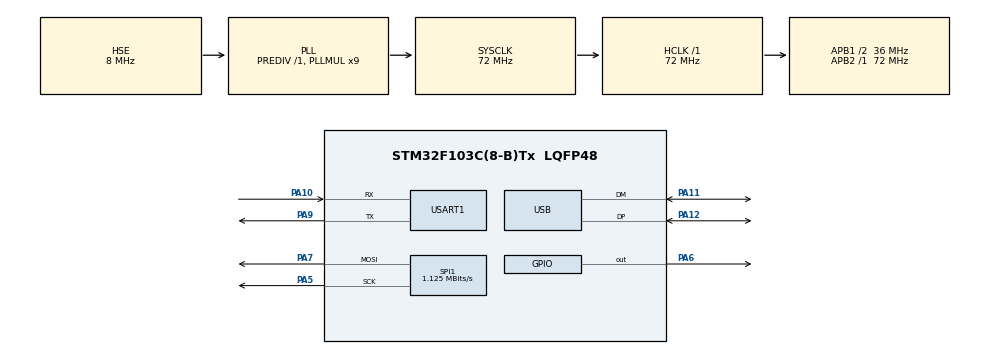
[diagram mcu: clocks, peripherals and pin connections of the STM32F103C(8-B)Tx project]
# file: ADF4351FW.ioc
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Dma.Request0=USART1_RX
Dma.Request1=USART1_TX
Dma.Request2=SPI1_TX
Dma.SPI1_TX.2.Direction=DMA_MEMORY_TO_PERIPH
Dma.SPI1_TX.2.Instance=DMA1_Channel3
Dma.SPI1_TX.2.MemDataAlignment=DMA_MDATAALIGN_BYTE
Dma.SPI1_TX.2.MemInc=DMA_MINC_ENABLE
Dma.SPI1_TX.2.Mode=DMA_NORMAL
Dma.SPI1_TX.2.PeriphDataAlignment=DMA_PDATAALIGN_BYTE
Dma.SPI1_TX.2.PeriphInc=DMA_PINC_DISABLE
Dma.SPI1_TX.2.Priority=DMA_PRIORITY_LOW
Dma.USART1_RX.0.Direction=DMA_PERIPH_TO_MEMORY
Dma.USART1_RX.0.Instance=DMA1_Channel5
Dma.USART1_RX.0.MemDataAlignment=DMA_MDATAALIGN_BYTE
Dma.USART1_RX.0.MemInc=DMA_MINC_ENABLE
Dma.USART1_RX.0.Mode=DMA_NORMAL
Dma.USART1_RX.0.PeriphDataAlignment=DMA_PDATAALIGN_BYTE
Dma.USART1_RX.0.PeriphInc=DMA_PINC_DISABLE
Dma.USART1_RX.0.Priority=DMA_PRIORITY_LOW
Dma.USART1_TX.1.Direction=DMA_MEMORY_TO_PERIPH
Dma.USART1_TX.1.Instance=DMA1_Channel4
Dma.USART1_TX.1.MemDataAlignment=DMA_MDATAALIGN_BYTE
Dma.USART1_TX.1.MemInc=DMA_MINC_ENABLE
Dma.USART1_TX.1.Mode=DMA_NORMAL
Dma.USART1_TX.1.PeriphDataAlignment=DMA_PDATAALIGN_BYTE
Dma.USART1_TX.1.PeriphInc=DMA_PINC_DISABLE
Dma.USART1_TX.1.Priority=DMA_PRIORITY_LOW
Mcu.Family=STM32F1
Mcu.Name=STM32F103C(8-B)Tx
Mcu.Package=LQFP48
NVIC.DMA1_Channel3_IRQn=true\:0\:0\:false\:false\:true\:false
NVIC.DMA1_Channel4_IRQn=true\:0\:0\:false\:false\:true\:false
NVIC.DMA1_Channel5_IRQn=true\:0\:0\:false\:false\:true\:false
NVIC.PriorityGroup=NVIC_PRIORITYGROUP_4
NVIC.USB_LP_CAN1_RX0_IRQn=true\:0\:0\:false\:false\:true\:false
PA10.Mode=Asynchronous
PA10.Signal=USART1_RX
PA11.Mode=Device
PA11.Signal=USB_DM
PA12.Mode=Device
PA12.Signal=USB_DP
PA13.Mode=Serial_Wire
PA13.Signal=SYS_JTMS-SWDIO
PA14.Mode=Serial_Wire
PA14.Signal=SYS_JTCK-SWCLK
PA5.Mode=TX_Only_Simplex_Unidirect_Master
PA5.Signal=SPI1_SCK
PA6.GPIO_Speed=GPIO_SPEED_FREQ_HIGH
PA6.PinState=GPIO_PIN_SET
PA6.Signal=GPIO_Output
PA7.Mode=TX_Only_Simplex_Unidirect_Master
PA7.Signal=SPI1_MOSI
PA9.Mode=Asynchronous
PA9.Signal=USART1_TX
PC14-OSC32_IN.Mode=LSE-External-Oscillator
PC14-OSC32_IN.Signal=RCC_OSC32_IN
PC15-OSC32_OUT.Mode=LSE-External-Oscillator
PC15-OSC32_OUT.Signal=RCC_OSC32_OUT
PD0-OSC_IN.Mode=HSE-External-Oscillator
PD0-OSC_IN.Signal=RCC_OSC_IN
PD1-OSC_OUT.Mode=HSE-External-Oscillator
PD1-OSC_OUT.Signal=RCC_OSC_OUT
ProjectManager.HeapSize=0x200
ProjectManager.StackSize=0x400
ProjectManager.TargetToolchain=SW4STM32
RCC.AHBFreq_Value=72000000
RCC.APB1CLKDivider=RCC_HCLK_DIV2
RCC.APB1Freq_Value=36000000
RCC.APB1TimFreq_Value=72000000
RCC.APB2Freq_Value=72000000
RCC.APB2TimFreq_Value=72000000
RCC.HCLKFreq_Value=72000000
RCC.PLLMUL=RCC_PLL_MUL9
RCC.SYSCLKFreq_VALUE=72000000
RCC.SYSCLKSource=RCC_SYSCLKSOURCE_PLLCLK
RCC.USBFreq_Value=48000000
RCC.USBPrescaler=RCC_USBCLKSOURCE_PLL_DIV1_5
SPI1.BaudRatePrescaler=SPI_BAUDRATEPRESCALER_64
SPI1.CalculateBaudRate=1.125 MBits/s
SPI1.DataSize=SPI_DATASIZE_8BIT
SPI1.Direction=SPI_DIRECTION_2LINES
SPI1.Mode=SPI_MODE_MASTER
SPI1.VirtualType=VM_MASTER
USART1.VirtualMode=VM_ASYNC
USB_DEVICE.CLASS_NAME_FS=CUSTOMHID
USB_DEVICE.USBD_CUSTOMHID_OUTREPORT_BUF_SIZE=64
USB_DEVICE.USBD_SELF_POWERED=0
USB_DEVICE.VirtualMode=CustomHid
USB_DEVICE.VirtualModeFS=Custom_Hid_FS
VP_USB_DEVICE_VS_USB_DEVICE_CUSTOM_HID_FS.Mode=CUSTOM_HID_FS
board=ADF4351FW

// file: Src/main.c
/**
  ******************************************************************************
  * @file           : main.c
  * @brief          : Main program body
  ******************************************************************************
  * This notice applies to any and all portions of this file
  * that are not between comment pairs USER CODE BEGIN and
  * USER CODE END. Other portions of this file, whether
  * inserted by the user or by software development tools
  * are owned by their respective copyright owners.
  *
  * Copyright (c) 2018 STMicroelectronics International N.V.
  * All rights reserved.
  *
  * Redistribution and use in source and binary forms, with or without
  * modification, are permitted, provided that the following conditions are met:
  *
  * 1. Redistribution of source code must retain the above copyright notice,
  *    this list of conditions and the following disclaimer.
  * 2. Redistributions in binary form must reproduce the above copyright notice,
  *    this list of conditions and the following disclaimer in the documentation
  *    and/or other materials provided with the distribution.
  * 3. Neither the name of STMicroelectronics nor the names of other
  *    contributors to this software may be used to endorse or promote products
  *    derived from this software without specific written permission.
  * 4. This software, including modifications and/or derivative works of this
  *    software, must execute solely and exclusively on microcontroller or
  *    microprocessor devices manufactured by or for STMicroelectronics.
  * 5. Redistribution and use of this software other than as permitted under
  *    this license is void and will automatically terminate your rights under
  *    this license.
  *
  * THIS SOFTWARE IS PROVIDED BY STMICROELECTRONICS AND CONTRIBUTORS "AS IS"
  * AND ANY EXPRESS, IMPLIED OR STATUTORY WARRANTIES, INCLUDING, BUT NOT
  * LIMITED TO, THE IMPLIED WARRANTIES OF MERCHANTABILITY, FITNESS FOR A
  * PARTICULAR PURPOSE AND NON-INFRINGEMENT OF THIRD PARTY INTELLECTUAL PROPERTY
  * RIGHTS ARE DISCLAIMED TO THE FULLEST EXTENT PERMITTED BY LAW. IN NO EVENT
  * SHALL STMICROELECTRONICS OR CONTRIBUTORS BE LIABLE FOR ANY DIRECT, INDIRECT,
  * INCIDENTAL, SPECIAL, EXEMPLARY, OR CONSEQUENTIAL DAMAGES (INCLUDING, BUT NOT
  * LIMITED TO, PROCUREMENT OF SUBSTITUTE GOODS OR SERVICES; LOSS OF USE, DATA,
  * OR PROFITS; OR BUSINESS INTERRUPTION) HOWEVER CAUSED AND ON ANY THEORY OF
  * LIABILITY, WHETHER IN CONTRACT, STRICT LIABILITY, OR TORT (INCLUDING
  * NEGLIGENCE OR OTHERWISE) ARISING IN ANY WAY OUT OF THE USE OF THIS SOFTWARE,
  * EVEN IF ADVISED OF THE POSSIBILITY OF SUCH DAMAGE.
  *
  ******************************************************************************
  */
#include "main.h"
#include "stm32f1xx_hal.h"
#include "usb_device.h"
#include "data_sender.h"

SPI_HandleTypeDef hspi1;
DMA_HandleTypeDef hdma_spi1_tx;

UART_HandleTypeDef huart1;
DMA_HandleTypeDef hdma_usart1_rx;
DMA_HandleTypeDef hdma_usart1_tx;

/* USER CODE BEGIN PV */
/* Private variables ---------------------------------------------------------*/

/* USER CODE END PV */

void SystemClock_Config(void);
static void MX_GPIO_Init(void);
static void MX_DMA_Init(void);
static void MX_USART1_UART_Init(void);
static void MX_SPI1_Init(void);

/* USER CODE BEGIN PFP */
/* Private function prototypes -----------------------------------------------*/

/* USER CODE END PFP */

/* USER CODE BEGIN 0 */

void HAL_SPI_TxCpltCallback(SPI_HandleTypeDef *hspi)
{
	ContinueSendingData(hspi);
}

void HAL_SYSTICK_Callback(void)
{
	ProcessDataAsync(&hspi1);
}
/* USER CODE END 0 */

int main(void)
{

  /* MCU Configuration----------------------------------------------------------*/

  /* Reset of all peripherals, Initializes the Flash interface and the Systick. */
  HAL_Init();

  /* Configure the system clock */
  SystemClock_Config();

  /* Initialize all configured peripherals */
  MX_GPIO_Init();
  MX_DMA_Init();
  MX_USB_DEVICE_Init();
  MX_USART1_UART_Init();
  MX_SPI1_Init();

  /* Infinite loop */
  while (1)
  {

  }

}

void SystemClock_Config(void)
{

  RCC_OscInitTypeDef RCC_OscInitStruct;
  RCC_ClkInitTypeDef RCC_ClkInitStruct;
  RCC_PeriphCLKInitTypeDef PeriphClkInit;

    /**Initializes the CPU, AHB and APB busses clocks
    */
  RCC_OscInitStruct.OscillatorType = RCC_OSCILLATORTYPE_HSE;
  RCC_OscInitStruct.HSEState = RCC_HSE_ON;
  RCC_OscInitStruct.HSEPredivValue = RCC_HSE_PREDIV_DIV1;
  RCC_OscInitStruct.HSIState = RCC_HSI_ON;
  RCC_OscInitStruct.PLL.PLLState = RCC_PLL_ON;
  RCC_OscInitStruct.PLL.PLLSource = RCC_PLLSOURCE_HSE;
  RCC_OscInitStruct.PLL.PLLMUL = RCC_PLL_MUL9;
  if (HAL_RCC_OscConfig(&RCC_OscInitStruct) != HAL_OK)
  {
    _Error_Handler(__FILE__, __LINE__);
  }

    /**Initializes the CPU, AHB and APB busses clocks
    */
  RCC_ClkInitStruct.ClockType = RCC_CLOCKTYPE_HCLK|RCC_CLOCKTYPE_SYSCLK
                              |RCC_CLOCKTYPE_PCLK1|RCC_CLOCKTYPE_PCLK2;
  RCC_ClkInitStruct.SYSCLKSource = RCC_SYSCLKSOURCE_PLLCLK;
  RCC_ClkInitStruct.AHBCLKDivider = RCC_SYSCLK_DIV1;
  RCC_ClkInitStruct.APB1CLKDivider = RCC_HCLK_DIV2;
  RCC_ClkInitStruct.APB2CLKDivider = RCC_HCLK_DIV1;

  if (HAL_RCC_ClockConfig(&RCC_ClkInitStruct, FLASH_LATENCY_2) != HAL_OK)
  {
    _Error_Handler(__FILE__, __LINE__);
  }

  PeriphClkInit.PeriphClockSelection = RCC_PERIPHCLK_USB;
  PeriphClkInit.UsbClockSelection = RCC_USBCLKSOURCE_PLL_DIV1_5;
  if (HAL_RCCEx_PeriphCLKConfig(&PeriphClkInit) != HAL_OK)
  {
    _Error_Handler(__FILE__, __LINE__);
  }

    /**Configure the Systick interrupt time
    */
  HAL_SYSTICK_Config(HAL_RCC_GetHCLKFreq()/1000);

    /**Configure the Systick
    */
  HAL_SYSTICK_CLKSourceConfig(SYSTICK_CLKSOURCE_HCLK);

  /* SysTick_IRQn interrupt configuration */
  HAL_NVIC_SetPriority(SysTick_IRQn, 0, 0);
}

/* SPI1 init function */
static void MX_SPI1_Init(void)
{

  /* SPI1 parameter configuration*/
  hspi1.Instance = SPI1;
  hspi1.Init.Mode = SPI_MODE_MASTER;
  hspi1.Init.Direction = SPI_DIRECTION_2LINES;
  hspi1.Init.DataSize = SPI_DATASIZE_8BIT;
  hspi1.Init.CLKPolarity = SPI_POLARITY_LOW;
  hspi1.Init.CLKPhase = SPI_PHASE_1EDGE;
  hspi1.Init.NSS = SPI_NSS_SOFT;
  hspi1.Init.BaudRatePrescaler = SPI_BAUDRATEPRESCALER_64;
  hspi1.Init.FirstBit = SPI_FIRSTBIT_MSB;
  hspi1.Init.TIMode = SPI_TIMODE_DISABLE;
  hspi1.Init.CRCCalculation = SPI_CRCCALCULATION_DISABLE;
  hspi1.Init.CRCPolynomial = 10;
  if (HAL_SPI_Init(&hspi1) != HAL_OK)
  {
    _Error_Handler(__FILE__, __LINE__);
  }

}

/* USART1 init function */
static void MX_USART1_UART_Init(void)
{

  huart1.Instance = USART1;
  huart1.Init.BaudRate = 115200;
  huart1.Init.WordLength = UART_WORDLENGTH_8B;
  huart1.Init.StopBits = UART_STOPBITS_1;
  huart1.Init.Parity = UART_PARITY_NONE;
  huart1.Init.Mode = UART_MODE_TX_RX;
  huart1.Init.HwFlowCtl = UART_HWCONTROL_NONE;
  huart1.Init.OverSampling = UART_OVERSAMPLING_16;
  if (HAL_UART_Init(&huart1) != HAL_OK)
  {
    _Error_Handler(__FILE__, __LINE__);
  }

}

static void MX_DMA_Init(void)
{
  /* DMA controller clock enable */
  __HAL_RCC_DMA1_CLK_ENABLE();

  /* DMA interrupt init */
  /* DMA1_Channel3_IRQn interrupt configuration */
  HAL_NVIC_SetPriority(DMA1_Channel3_IRQn, 0, 0);
  HAL_NVIC_EnableIRQ(DMA1_Channel3_IRQn);
  /* DMA1_Channel4_IRQn interrupt configuration */
  HAL_NVIC_SetPriority(DMA1_Channel4_IRQn, 0, 0);
  HAL_NVIC_EnableIRQ(DMA1_Channel4_IRQn);
  /* DMA1_Channel5_IRQn interrupt configuration */
  HAL_NVIC_SetPriority(DMA1_Channel5_IRQn, 0, 0);
  HAL_NVIC_EnableIRQ(DMA1_Channel5_IRQn);

}

/** Configure pins as
        * Analog
        * Input
        * Output
        * EVENT_OUT
        * EXTI
*/
static void MX_GPIO_Init(void)
{

  GPIO_InitTypeDef GPIO_InitStruct;

  /* GPIO Ports Clock Enable */
  __HAL_RCC_GPIOC_CLK_ENABLE();
  __HAL_RCC_GPIOD_CLK_ENABLE();
  __HAL_RCC_GPIOA_CLK_ENABLE();

  /*Configure GPIO pin Output Level */
  HAL_GPIO_WritePin(GPIOA, GPIO_PIN_6, GPIO_PIN_SET);

  /*Configure GPIO pin : PA6 */
  GPIO_InitStruct.Pin = GPIO_PIN_6;
  GPIO_InitStruct.Mode = GPIO_MODE_OUTPUT_PP;
  GPIO_InitStruct.Speed = GPIO_SPEED_FREQ_HIGH;
  HAL_GPIO_Init(GPIOA, &GPIO_InitStruct);

}

void _Error_Handler(char *file, int line)
{
  while(1)
  {
  }
}

/************************ (C) COPYRIGHT STMicroelectronics *****END OF FILE****/
